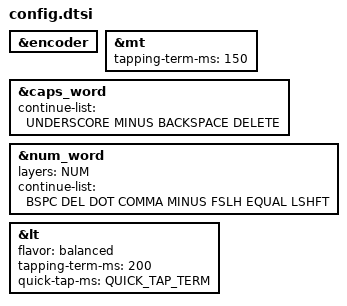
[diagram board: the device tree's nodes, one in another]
#define XXX &none
#define ___ &trans

#define DEF 0
#define QWERTY 1
#define NAV 2
#define NUM 3
#define SYM 4
#define FUNC 5
#define MEDIA 6
#define SYS 7

#define KEYS_L 0 1 2 3 4 10 11 12 13 14 15 22 23 24 25 26 27  // left-hand keys
#define KEYS_R 5 6 7 8 9 16 17 18 19 20 21 28 29 30 31 32 33  // right-hand keys
#define THUMBS 34 35 36 37 38 39
#define WAY 40 41 42 43 44
#define ENCODER 45

/*                                      40 KEY MATRIX / LAYOUT MAPPING
      ╭────────────────────┬────────────────────╮         ╭─────────────────────┬─────────────────────╮
  ╭───╯  0   1   2   3   4 │  5   6   7   8   9 ╰───╮ ╭───╯ LT4 LT3 LT2 LT1 LT0 │ RT0 RT1 RT2 RT3 RT4 ╰───╮
  │ 10  11  12  13  14  15 │ 16  17  18  19  20  21 │ │ LM5 LM4 LM3 LM2 LM1 LM0 │ RM0 RM1 RM2 RM3 RM4 RM5 │
  │ 22  23  24  25  26  27 │ 28  29  30  31  32  33 │ │ LB5 LB4 LB3 LB2 LB1 LB0 │ RB0 RB1 RB2 RB3 RB4 RB5 │
  ╰───────────╮ 34  35  36 │ 37  38  39 ╭───────────╯ ╰───────────╮ LH2 LH1 LH0 │ RH0 RH1 RH2 ╭───────────╯
  ╭───────────┴────────┬───┴─────────┬──┴───╮         ╭───────────┴────────┬────┴──────────┬──┴──╮
  │ 40  41  42  43  44 │             │  45  │         │ WL  WD  WU  WR  WC │               │ ENC │
  ╰────────────────────╯             ╰──────╯         ╰────────────────────╯               ╰─────╯*/

#define LT4 0   // left-top row
#define LT3 1
#define LT2 2
#define LT1 3
#define LT0 4
#define RT0 5   // right-top row
#define RT1 6
#define RT2 7
#define RT3 8
#define RT4 9
#define LM5 10  // left-middle row
#define LM4 11
#define LM3 12
#define LM2 13
#define LM1 14
#define LM0 15
#define RM0 16  // right-middle row
#define RM1 17
#define RM2 18
#define RM3 19
#define RM4 20
#define RM5 21
#define LB5 22  // left-bottom row
#define LB4 23
#define LB3 24
#define LB2 25
#define LB1 26
#define LB0 27
#define RB0 28  // right-bottom row
#define RB1 29
#define RB2 30
#define RB3 31
#define RB4 32
#define RB5 33
#define LH2  34  // left thumb keys
#define LH1  35
#define LH0  36
#define RH0  37  // right thumb keys
#define RH1  38
#define RH2  39
#define WL  40  // 5-way key
#define WD  41
#define WU  42
#define WR  43
#define WC  44
#define ENC  45  // encoder

&encoder { status = "okay"; };

&mt { tapping-term-ms = <150>; };

&caps_word {
    continue-list = <UNDERSCORE MINUS BACKSPACE DELETE>;
};

&num_word {  // num-word
    layers = <NUM>;
    continue-list = <BSPC DEL DOT COMMA MINUS FSLH EQUAL LSHFT>;
};

#define TAPPING_TERM 175
#define TD_TAPPING_TERM 225
#define QUICK_TAP_TERM 175
#define ADAPTIVE_KEY_TIMEOUT 500

&lt {  // layer-tap config
    flavor = "balanced";
    tapping-term-ms = <200>;
    quick-tap-ms = <QUICK_TAP_TERM>;
};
